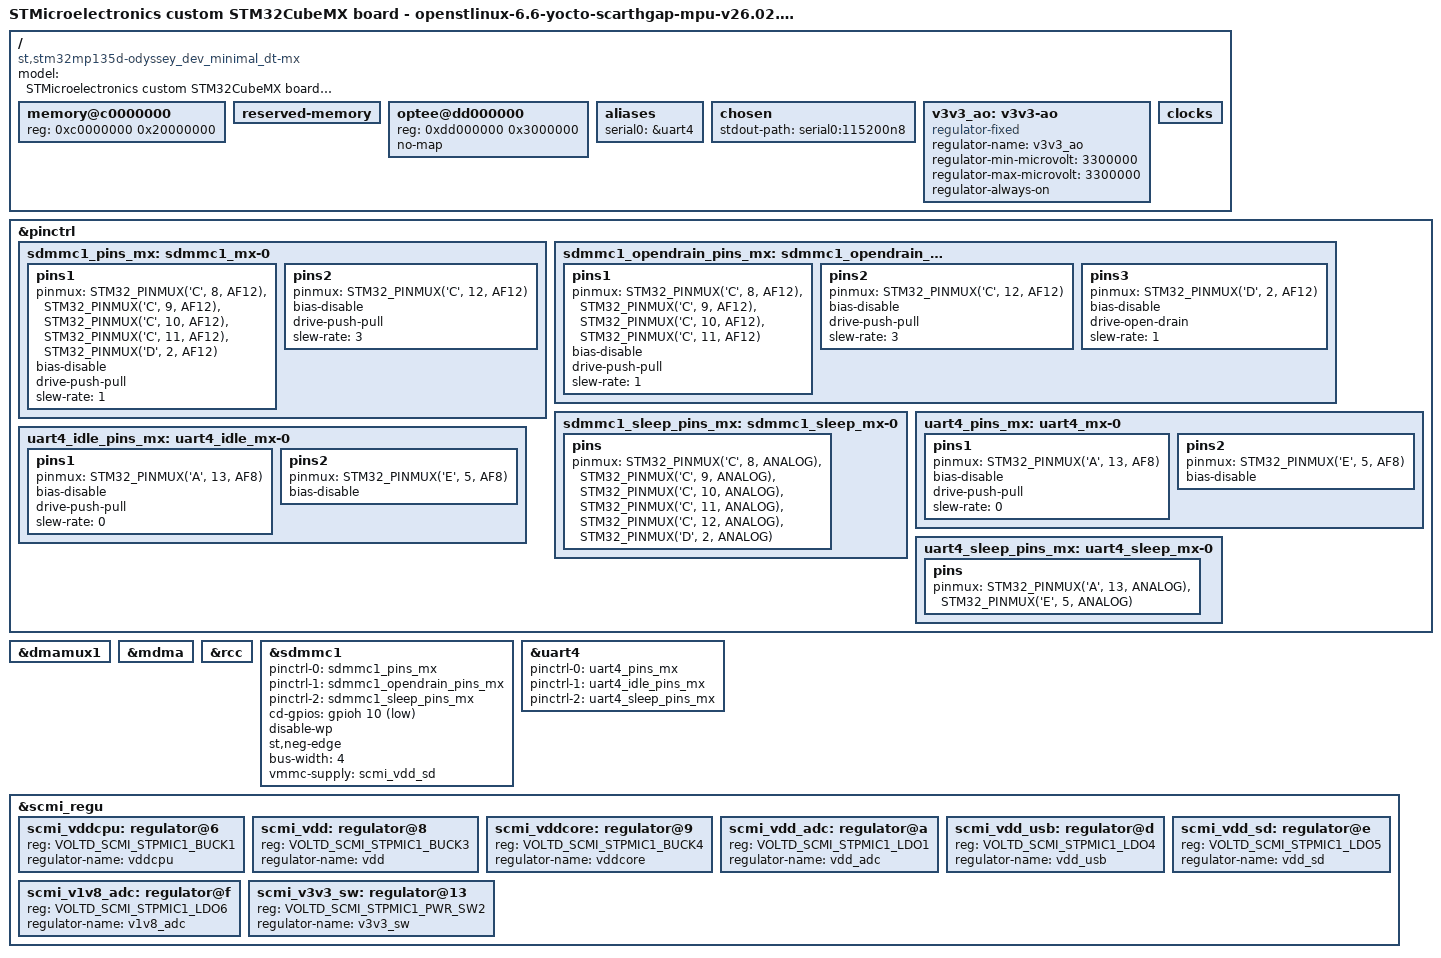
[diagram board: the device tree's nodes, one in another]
// SPDX-License-Identifier: (GPL-2.0+ OR BSD-3-Clause)
/*
 * Copyright (C) 2026, STMicroelectronics - All Rights Reserved
 * Author: STM32CubeMX code generation for STMicroelectronics.
 */

/* For more information on Device Tree configuration, please refer to
 * https://wiki.st.com/stm32mpu/wiki/Category:Device_tree_configuration
 */

/dts-v1/;

#include <dt-bindings/pinctrl/stm32-pinfunc.h>
#include "stm32mp135.dtsi"
#include "stm32mp13xd.dtsi"

/* USER CODE BEGIN includes */
#include <dt-bindings/gpio/gpio.h>
/* USER CODE END includes */

/ {
	model = "STMicroelectronics custom STM32CubeMX board - openstlinux-6.6-yocto-scarthgap-mpu-v26.02.18";
	compatible = "st,stm32mp135d-odyssey_dev_minimal_dt-mx", "st,stm32mp135";

	memory@c0000000 {
		device_type = "memory";
		reg = <0xc0000000 0x20000000>;

		/* USER CODE BEGIN memory */
		/* USER CODE END memory */
	};

	reserved-memory {
		#address-cells = <1>;
		#size-cells = <1>;
		ranges;

		/* USER CODE BEGIN reserved-memory */
		/* USER CODE END reserved-memory */
	};

	/* USER CODE BEGIN root */
	optee@dd000000{
		reg = <0xdd000000 0x3000000>;
		no-map;
	};

	aliases{
		serial0 = &uart4;
	};

	chosen{
		stdout-path = "serial0:115200n8";
		#address-cells = <1>;
		#size-cells = <1>;
		ranges;
	};

	v3v3_ao:v3v3-ao{
		compatible = "regulator-fixed";
		regulator-name = "v3v3_ao";
		regulator-min-microvolt = <3300000>;
		regulator-max-microvolt = <3300000>;
		regulator-always-on;
	};	
	/* USER CODE END root */

	clocks{

		/* USER CODE BEGIN clocks */
		/* USER CODE END clocks */
	};

}; /*root*/

&pinctrl {
	sdmmc1_pins_mx: sdmmc1_mx-0 {
		pins1 {
			pinmux = <STM32_PINMUX('C', 8, AF12)>, /* SDMMC1_D0 */
				 <STM32_PINMUX('C', 9, AF12)>, /* SDMMC1_D1 */
				 <STM32_PINMUX('C', 10, AF12)>, /* SDMMC1_D2 */
				 <STM32_PINMUX('C', 11, AF12)>, /* SDMMC1_D3 */
				 <STM32_PINMUX('D', 2, AF12)>; /* SDMMC1_CMD */
			bias-disable;
			drive-push-pull;
			slew-rate = <1>;
		};
		pins2 {
			pinmux = <STM32_PINMUX('C', 12, AF12)>; /* SDMMC1_CK */
			bias-disable;
			drive-push-pull;
			slew-rate = <3>;
		};
	};

	sdmmc1_opendrain_pins_mx: sdmmc1_opendrain_mx-0 {
		pins1 {
			pinmux = <STM32_PINMUX('C', 8, AF12)>, /* SDMMC1_D0 */
				 <STM32_PINMUX('C', 9, AF12)>, /* SDMMC1_D1 */
				 <STM32_PINMUX('C', 10, AF12)>, /* SDMMC1_D2 */
				 <STM32_PINMUX('C', 11, AF12)>; /* SDMMC1_D3 */
			bias-disable;
			drive-push-pull;
			slew-rate = <1>;
		};
		pins2 {
			pinmux = <STM32_PINMUX('C', 12, AF12)>; /* SDMMC1_CK */
			bias-disable;
			drive-push-pull;
			slew-rate = <3>;
		};
		pins3 {
			pinmux = <STM32_PINMUX('D', 2, AF12)>; /* SDMMC1_CMD */
			bias-disable;
			drive-open-drain;
			slew-rate = <1>;
		};
	};

	sdmmc1_sleep_pins_mx: sdmmc1_sleep_mx-0 {
		pins {
			pinmux = <STM32_PINMUX('C', 8, ANALOG)>, /* SDMMC1_D0 */
				 <STM32_PINMUX('C', 9, ANALOG)>, /* SDMMC1_D1 */
				 <STM32_PINMUX('C', 10, ANALOG)>, /* SDMMC1_D2 */
				 <STM32_PINMUX('C', 11, ANALOG)>, /* SDMMC1_D3 */
				 <STM32_PINMUX('C', 12, ANALOG)>, /* SDMMC1_CK */
				 <STM32_PINMUX('D', 2, ANALOG)>; /* SDMMC1_CMD */
		};
	};

	uart4_pins_mx: uart4_mx-0 {
		pins1 {
			pinmux = <STM32_PINMUX('A', 13, AF8)>; /* UART4_TX */
			bias-disable;
			drive-push-pull;
			slew-rate = <0>;
		};
		pins2 {
			pinmux = <STM32_PINMUX('E', 5, AF8)>; /* UART4_RX */
			bias-disable;
		};
	};

	uart4_idle_pins_mx: uart4_idle_mx-0 {
		pins1 {
			pinmux = <STM32_PINMUX('A', 13, AF8)>; /* UART4_TX */
			bias-disable;
			drive-push-pull;
			slew-rate = <0>;
		};
		pins2 {
			pinmux = <STM32_PINMUX('E', 5, AF8)>; /* UART4_RX */
			bias-disable;
		};
	};

	uart4_sleep_pins_mx: uart4_sleep_mx-0 {
		pins {
			pinmux = <STM32_PINMUX('A', 13, ANALOG)>, /* UART4_TX */
				 <STM32_PINMUX('E', 5, ANALOG)>; /* UART4_RX */
		};
	};

	/* USER CODE BEGIN pinctrl */
	/* USER CODE END pinctrl */
};

&dmamux1 {
	status = "okay";

	/* !!! log : Warning - No dma master found  !!! */

	/* USER CODE BEGIN dmamux1 */
	/* USER CODE END dmamux1 */
};

&mdma {
	status = "okay";

	/* USER CODE BEGIN mdma */
	/* USER CODE END mdma */
};

&rcc {
	status = "okay";

	/* USER CODE BEGIN rcc */
	/* USER CODE END rcc */
};

&sdmmc1 {
	pinctrl-names = "default", "opendrain", "sleep";
	pinctrl-0 = <&sdmmc1_pins_mx>;
	pinctrl-1 = <&sdmmc1_opendrain_pins_mx>;
	pinctrl-2 = <&sdmmc1_sleep_pins_mx>;
	status = "okay";

	/* USER CODE BEGIN sdmmc1 */
	cd-gpios = <&gpioh 10 (GPIO_ACTIVE_LOW | GPIO_PULL_UP)>;
	disable-wp;
	st,neg-edge;
	bus-width = <4>;
	vmmc-supply = <&scmi_vdd_sd>;
	/* USER CODE END sdmmc1 */
};

&uart4 {
	pinctrl-names = "default", "idle", "sleep";
	pinctrl-0 = <&uart4_pins_mx>;
	pinctrl-1 = <&uart4_idle_pins_mx>;
	pinctrl-2 = <&uart4_sleep_pins_mx>;
	status = "okay";

	/* USER CODE BEGIN uart4 */
	/delete-property/ dmas;
	/delete-property/ dma-names;	
	/* USER CODE END uart4 */
};

/* USER CODE BEGIN addons */
&scmi_regu {
	scmi_vddcpu:regulator@6{
		reg = <VOLTD_SCMI_STPMIC1_BUCK1>;
		regulator-name = "vddcpu";
	};

	scmi_vdd:regulator@8{
		reg = <VOLTD_SCMI_STPMIC1_BUCK3>;
		regulator-name = "vdd";
	};

	scmi_vddcore:regulator@9{
		reg = <VOLTD_SCMI_STPMIC1_BUCK4>;
		regulator-name = "vddcore";
	};

	scmi_vdd_adc:regulator@a{
		reg = <VOLTD_SCMI_STPMIC1_LDO1>;
		regulator-name = "vdd_adc";
	};

	scmi_vdd_usb:regulator@d{
		reg = <VOLTD_SCMI_STPMIC1_LDO4>;
		regulator-name = "vdd_usb";
	};

	scmi_vdd_sd:regulator@e{
		reg = <VOLTD_SCMI_STPMIC1_LDO5>;
		regulator-name = "vdd_sd";
	};

	scmi_v1v8_adc:regulator@f{
		reg = <VOLTD_SCMI_STPMIC1_LDO6>;
		regulator-name = "v1v8_adc";
	};

	scmi_v3v3_sw:regulator@13{
		reg = <VOLTD_SCMI_STPMIC1_PWR_SW2>;
		regulator-name = "v3v3_sw";
	};
};
/* USER CODE END addons */

